# AT32F402 register map
Vendor: Keil; Series: AT32F402; File version: 1.0
CPU: CM4 r0p1, little endian, no MPU, FPU, 4 interrupt priority bits
Registers are 32-bit, read-write, reset 0x0 unless marked. A register's access mark holds for its fields unless they carry their own. Offsets are from the block's base; [hi:lo] are bit positions; lines under a group give offsets from that group; {n}, {i} and the like mark numbered series; 'fields as' and 'values as' point back to an identical list; <NAME> marks a mode.

## DMA1 — DMA controller
Base 0x40026000
Same registers: DMA2 0x40026400
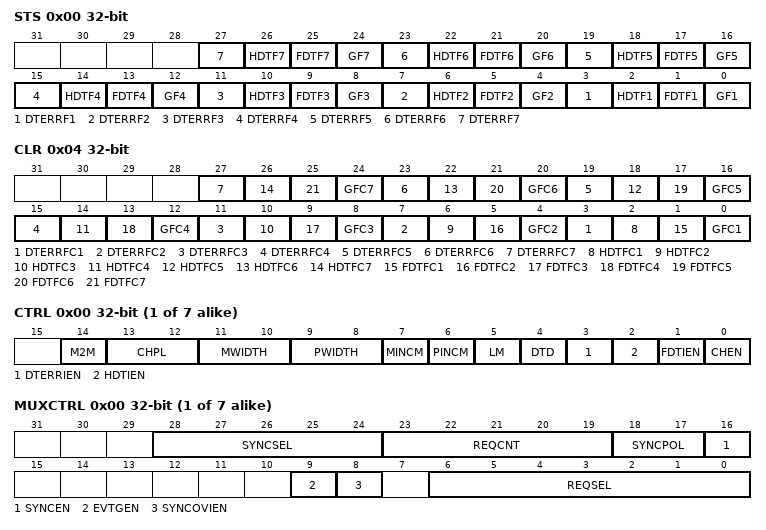
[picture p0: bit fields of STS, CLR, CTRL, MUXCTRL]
0x00 STS ro — DMA interrupt status register (DMA_STS)
  [4n-1] DTERRF{n} (n=1..7) — Channel {n} data transfer error event flag
    0=NoTransferError; 1=TransferError (A transfer error occurred)
  [4n-2] HDTF{n} (n=1..7) — Channel {n} half transfer event flag
    0=NoHalfTransfer; 1=HalfTransfer (A half transfer occurred)
  [4n-3] FDTF{n} (n=1..7) — Channel {n} data transfer complete event flag
    0=NoTransferComplete; 1=TransferComplete (A transfer complete occurred)
  [4n-4] GF{n} (n=1..7) — Channel {n} global event flag
    0=NoEvent; 1=Event (An event occurred (transfer error, half transfer or transfer complete))
0x04 CLR — DMA interrupt flag clear register (DMA_CLR)
  [4n-1] DTERRFC{n} (n=1..7) write-1-clears — Channel {n} data transfer error flag clear
    1=Clear the transfer error flag
  [4n-2] HDTFC{n} (n=1..7) write-1-clears — Channel {n} half transfer flag clear
    1=Clear the half transfer flag
  [4n-3] FDTFC{n} (n=1..7) write-1-clears — Channel {n} data transfer complete flag clear
    1=Clear the transfer complete flag
  [4n-4] GFC{n} (n=1..7) write-1-clears — Channel {n} global flag clear
    1=Clear all flags DTERRFx, HDTFx, FDTFx and GFx
0x08 Channel{i} (i=1..7; step 0x14) group — DMA Channel {i}
  0x00 CTRL — DMA channel configuration register
    [14] M2M — Memory to memory mode
      on read: 0=Disabled (Memory to memory mode is disabled); 1=Enabled (Memory to memory mode is enabled) | on write: 0=Disable (Memory to memory mode disable); 1=Enable (Memory to memory mode enable)
    [13:12] CHPL — Channel Priority level
      0=Low; 1=Medium; 2=High; 3=VeryHigh
    [11:10] MWIDTH — Memory data bit width
      0=bit8 (8 bits); 1=bit16 (16 bits); 2=bit32 (32 bits)
    [9:8] PWIDTH — Peripheral data bit width
      0=bit8 (8 bits); 1=bit16 (16 bits); 2=bit32 (32 bits)
    [7] MINCM — Memory increment mode
      on read: 0=Disabled (Memory address increment is disabled); 1=Enabled (Memory address increment is enabled) | on write: 0=Disable (Memory address increment disable); 1=Enable (Memory address increment enable)
    [6] PINCM — Peripheral increment mode
      on read: 0=Disabled (Peripheral address increment is disabled); 1=Enabled (Peripheral address increment is enabled) | on write: 0=Disable (Peripheral address increment disable); 1=Enable (Peripheral address increment enable)
    [5] LM — Loop mode
      on read: 0=Disabled (Circular mode is disabled); 1=Enabled (Circular mode is enabled) | on write: 0=Disable (Circular mode disable); 1=Enable (Circular mode enable)
    [4] DTD — Data transfer direction
      0=Peripherals (Read from peripherals); 1=Memory (Read from memory)
    [3] DTERRIEN — Transfer error interrupt enable
      on read: 0=Disabled (Data transfer error interrupt is disabled); 1=Enabled (Data transfer error interrupt is enabled) | on write: 0=Disable (Data transfer error interrupt disable); 1=Enable (Data transfer error interrupt enable)
    [2] HDTIEN — Half transfer interrupt enable
      on read: 0=Disabled (Half-transfer interrupt is disabled); 1=Enabled (Half-transfer interrupt is enabled) | on write: 0=Disable (Half-transfer interrupt disable); 1=Enable (Half-transfer interrupt enable)
    [1] FDTIEN — Transfer complete interrupt enable
      on read: 0=Disabled (Transfer complete interrupt is disabled); 1=Enabled (Transfer complete interrupt is enabled) | on write: 0=Disable (Transfer complete interrupt disable); 1=Enable (Transfer complete interrupt enable)
    [0] CHEN — Channel enable
      on read: 0=Disabled (Channel is disabled); 1=Enabled (Channel is enabled) | on write: 0=Disable (Channel disable); 1=Enable (Channel enable)
  0x04 DTCNT — DMA channel number of data to transfer register
    [15:0] CNT — Number of data to transfer
  0x08 PADDR — DMA channel peripheral base address register
  0x0C MADDR — DMA channel memory base address register
0x100 DMA_MUXSEL — DMAMUX Table Selection
  [0] TBL_SEL — Multiplexer Table Select
    0=Normal table; 1=Flexible mapping table
{0x100+4i} ChannelMux{i} (i=1..7) group — Channel {i} mux
  0x00 MUXCTRL — DMA channel mux control register
    [28:24] SYNCSEL — Synchronization Identification
    [23:19] REQCNT — Number of DMA requests
    [18:17] SYNCPOL — Synchronization polarity
      0=NoEvents; 1=RisingEdge; 2=FallingEdge; 3=BothEdges (Rising and falling edges)
    [16] SYNCEN — Synchronization enable
      on read: 0=Disabled (Channel synchronization is disabled); 1=Enabled (Channel synchronization is enabled) | on write: 0=Disable (Channel synchronization disable); 1=Enable (Channel synchronization enable)
    [9] EVTGEN — Event generation enable
      on read: 0=Disabled (Event generation is disabled); 1=Enabled (Event generation is enabled) | on write: 0=Disable (Event generation disable); 1=Enable (Event generation enable)
    [8] SYNCOVIEN — Synchronization overrun interrupt enable
      on read: 0=Disabled (Channel synchronization overrun interrupt is disabled); 1=Enabled (Channel synchronization overrun interrupt is enabled) | on write: 0=Disable (Channel synchronization overrun interrupt disable); 1=Enable (Channel synchronization overrun interrupt enable)
    [6:0] REQSEL — DMA request select
{0x11C+4i} GeneratorChannelMux{i} (i=1..4) group — Cluster GeneratorChannelMux{i}, containing MUXG?CTRL
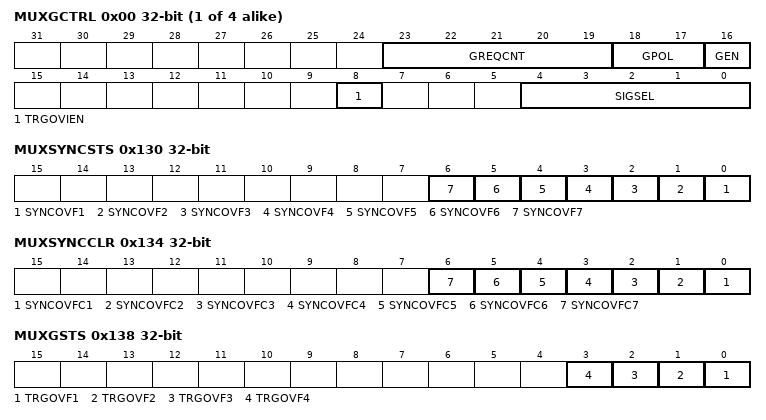
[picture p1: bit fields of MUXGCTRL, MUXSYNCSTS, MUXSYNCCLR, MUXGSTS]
  0x00 MUXGCTRL — DMA generator channel mux control register
    [23:19] GREQCNT — Number of DMA requests to be generated
    [18:17] GPOL — DMA request generator trigger polarity
      values as ChannelMux1.MUXCTRL.SYNCPOL
    [16] GEN — DMA request generator enable
      on read: 0=Disabled (DMA request generation is disabled); 1=Enabled (DMA request generation is enabled) | on write: 0=Disable (DMA request generation disable); 1=Enable (DMA request generation enable)
    [8] TRGOVIEN — Trigger overrun interrupt enable
      on read: 0=Disabled (Trigger overrun interrupt is disabled); 1=Enabled (Trigger overrun interrupt is enabled) | on write: 0=Disable (Trigger overrun interrupt disable); 1=Enable (Trigger overrun interrupt enable)
    [4:0] SIGSEL — Signal select
0x130 MUXSYNCSTS — Channel Interrupt Status Register
  [n-1] SYNCOVF{n} (n=1..7) ro — Channel {n} synchronization overrun flag
    0=NoOverrun (No synchronization overrun); 1=Overrun (A synchronization overrun occurred (DMA request count < REQCNT))
0x134 MUXSYNCCLR — Channel Interrupt Clear Flag Register
  [n-1] SYNCOVFC{n} (n=1..7) write-1-clears — Channel {n} synchronization overrun flag clear
    on write: 1=Clear synchronization overrun flag
0x138 MUXGSTS — Generator Interrupt Status Register
  [n-1] TRGOVF{n} (n=1..4) ro — Channel {n} trigger overrun flag
    0=NoOverrun (No trigger overrun); 1=Overrun (A trigger overrun occurred (DMA request count < GREQCNT))
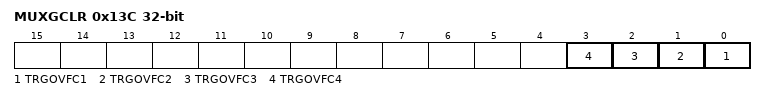
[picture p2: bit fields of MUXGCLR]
0x13C MUXGCLR — Generator Interrupt Clear Flag Register
  [n-1] TRGOVFC{n} (n=1..4) write-1-clears — Channel {n} trigger overrun flag clear
    on write: 1=Clear trigger overrun flag
